# ADC_ADC_CFG_502C0000h register map
Vendor: Texas Instruments
Registers are 16-bit, read-write, reset values left out (the file's numbers can be read two ways) unless marked. A register's access mark holds for its fields unless they carry their own. Offsets are as the file gives them; [hi:lo] are bit positions; {n}, {i} and the like mark numbered series.

## ADC_CFG (part 3 of 3)
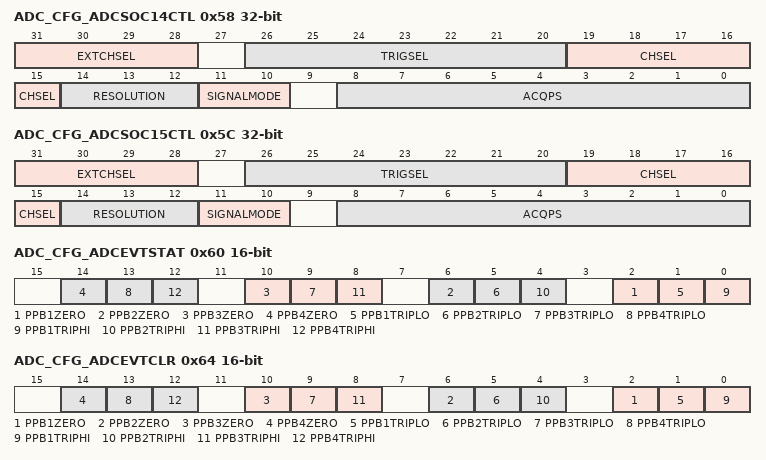
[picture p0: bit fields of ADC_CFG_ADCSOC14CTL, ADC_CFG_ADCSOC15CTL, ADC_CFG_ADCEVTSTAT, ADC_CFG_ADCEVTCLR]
0x58 ADC_CFG_ADCSOC14CTL 32-bit access per field — ADC SOC14 Control Register.
  [31:28] EXTCHSEL rw — SOC14 External Channel Mux Select. Selects the external mux combination to output when SOC14 is received by the ADC. Some or all of the ADCEXTMUX lines can be enabled via the device GPIO mux to control an external analog mux.
  [26:20] TRIGSEL rw — SOC14 Trigger Source Select. Along with the SOC14 field in the ADCINTSOCSEL1 register, this bit field configures which trigger will set the SOC14 flag in the ADCSOCFLG1 register to initiate a conversion to start once priority is given to it. Note: SOCFRC1 register can always be used to software trigger SOCs in addition to any hardware trigger configuration. 00h ADCTRIG0 - Software only 01h ADCTRIG1 - RTI0 Timer 02h ADCTRIG2 - RTI1 Timer 03h ADCTRIG3 - RTI2 Timer 04h ADCTRIG4 - RTI3 Timer 05h ADCTRIG5 - InputXBAR.Out[5] 06h ADCTRIG6 - spare 07h ADCTRIG7 - spare 08h ADCTRIG8 - EPWM0, ADCSOCA 09h ADCTRIG9 - EPWM0, ADCSOCB 0Ah ADCTRIG10 - EPWM1, ADCSOCA 0Bh ADCTRIG11 - EPWM1, ADCSOCB 0Ch ADCTRIG12 - EPWM2, ADCSOCA 0Dh ADCTRIG13 - EPWM2, ADCSOCB 0Eh ADCTRIG14 - EPWM3, ADCSOCA 0Fh ADCTRIG15 - EPWM3, ADCSOCB .... EPWM4 to EPWM27 40h ADCTRIG64 - EPWM28, ADCSOCA 41h ADCTRIG65 - EPWM28, ADCSOCB 42h ADCTRIG66 - EPWM29, ADCSOCA 43h ADCTRIG67 - EPWM29, ADCSOCB 44h ADCTRIG68 - EPWM30, ADCSOCA 45h ADCTRIG69 - EPWM30, ADCSOCB 46h ADCTRIG70 - EPWM31, ADCSOCA 47h ADCTRIG71 - EPWM31, ADCSOCB 48h ADCTRIG72 - ECAP0, TRIGOUT .... ECAP1 to ECAP8 51h ADCTRIG81 - ECAP9, TRIGOUT 52h ADCTRIG82 - ECAP10, TRIGOUT .... 57h ADCTRIG87 - ECAP15, TRIGOUT 58h ADCTRIG88 - RTI4 Timer 59h ADCTRIG89 - RTI5 Timer 5Ah ADCTRIG90 - RTI6 Timer 5Bh ADCTRIG91 - RTI7 Timer .... 7Fh ADCTRIG127 - REP2TRIG - these are not external trigger signals on the ADC IP port. We need to configure them for internal selection of repeater triggers.
  [19:15] CHSEL rw — SOC14 Channel Select. Selects the channel to be converted when SOC14 is received by the ADC. Single-ended Signaling Mode [SIGNALMODE = 0]: 00h ADCIN0 01h ADCIN1 02h ADCIN2 03h ADCIN3 ... 1Dh ADCIN29 1Eh ADCIN30 1Fh ADCIN31 Differential Signaling Mode [SIGNALMODE = 1]: 00h ADCIN0 [non-inverting] and ADCIN1 [inverting] 01h ADCIN0 [non-inverting] and ADCIN1 [inverting] 02h ADCIN2 [non-inverting] and ADCIN3 [inverting] 03h ADCIN2 [non-inverting] and ADCIN3 [inverting] 04h ADCIN4 [non-inverting] and ADCIN5 [inverting] 05h ADCIN4 [non-inverting] and ADCIN5 [inverting] ... 0Eh ADCIN26 [non-inverting] and ADCIN27 [inverting] 0Fh ADCIN26 [non-inverting] and ADCIN27 [inverting] 10h ADCIN28 [non-inverting] and ADCIN29 [inverting] 11h ADCIN28 [non-inverting] and ADCIN29 [inverting] 1Eh ADCIN30 [non-inverting] and ADCIN31 [inverting] 1Fh ADCIN30 [non-inverting] and ADCIN31 [inverting]
  [14:12] RESOLUTION ro — Placeholder for per-SOC resolution
  [11:10] SIGNALMODE ro — Placeholder for per-SOC signal mode
  [8:0] ACQPS rw — SOC14 Acquisition Prescale. Controls the sample and hold window for this SOC. 000h Reserved 001h Reserved 002h Sample window is 3 system clock cycles wide 003h Sample window is 4 system clock cycles wide ... 1FFh Sample window is 512 system clock cycles wide The configured acquisition time must be at least as long as one ADCCLK cycle for correct ADC operation. The configured acquisition time must also be at least 3 SYSCLK cycles long. The device datasheet will also specify a minimum sample and hold window duration.
0x5C ADC_CFG_ADCSOC15CTL 32-bit access per field — ADC SOC15 Control Register.
  [31:28] EXTCHSEL rw — SOC15 External Channel Mux Select. Selects the external mux combination to output when SOC15 is received by the ADC. Some or all of the ADCEXTMUX lines can be enabled via the device GPIO mux to control an external analog mux.
  [26:20] TRIGSEL rw — SOC15 Trigger Source Select. Along with the SOC15 field in the ADCINTSOCSEL1 register, this bit field configures which trigger will set the SOC15 flag in the ADCSOCFLG1 register to initiate a conversion to start once priority is given to it. Note: SOCFRC1 register can always be used to software trigger SOCs in addition to any hardware trigger configuration. 00h ADCTRIG0 - Software only 01h ADCTRIG1 - RTI0 Timer 02h ADCTRIG2 - RTI1 Timer 03h ADCTRIG3 - RTI2 Timer 04h ADCTRIG4 - RTI3 Timer 05h ADCTRIG5 - InputXBAR.Out[5] 06h ADCTRIG6 - spare 07h ADCTRIG7 - spare 08h ADCTRIG8 - EPWM0, ADCSOCA 09h ADCTRIG9 - EPWM0, ADCSOCB 0Ah ADCTRIG10 - EPWM1, ADCSOCA 0Bh ADCTRIG11 - EPWM1, ADCSOCB 0Ch ADCTRIG12 - EPWM2, ADCSOCA 0Dh ADCTRIG13 - EPWM2, ADCSOCB 0Eh ADCTRIG14 - EPWM3, ADCSOCA 0Fh ADCTRIG15 - EPWM3, ADCSOCB .... EPWM4 to EPWM27 40h ADCTRIG64 - EPWM28, ADCSOCA 41h ADCTRIG65 - EPWM28, ADCSOCB 42h ADCTRIG66 - EPWM29, ADCSOCA 43h ADCTRIG67 - EPWM29, ADCSOCB 44h ADCTRIG68 - EPWM30, ADCSOCA 45h ADCTRIG69 - EPWM30, ADCSOCB 46h ADCTRIG70 - EPWM31, ADCSOCA 47h ADCTRIG71 - EPWM31, ADCSOCB 48h ADCTRIG72 - ECAP0, TRIGOUT .... ECAP1 to ECAP8 51h ADCTRIG81 - ECAP9, TRIGOUT 52h ADCTRIG82 - ECAP10, TRIGOUT .... 57h ADCTRIG87 - ECAP15, TRIGOUT 58h ADCTRIG88 - RTI4 Timer 59h ADCTRIG89 - RTI5 Timer 5Ah ADCTRIG90 - RTI6 Timer 5Bh ADCTRIG91 - RTI7 Timer .... 7Fh ADCTRIG127 - REP2TRIG - these are not external trigger signals on the ADC IP port. We need to configure them for internal selection of repeater triggers.
  [19:15] CHSEL rw — SOC15 Channel Select. Selects the channel to be converted when SOC15 is received by the ADC. Single-ended Signaling Mode [SIGNALMODE = 0]: 00h ADCIN0 01h ADCIN1 02h ADCIN2 03h ADCIN3 ... 1Dh ADCIN29 1Eh ADCIN30 1Fh ADCIN31 Differential Signaling Mode [SIGNALMODE = 1]: 00h ADCIN0 [non-inverting] and ADCIN1 [inverting] 01h ADCIN0 [non-inverting] and ADCIN1 [inverting] 02h ADCIN2 [non-inverting] and ADCIN3 [inverting] 03h ADCIN2 [non-inverting] and ADCIN3 [inverting] 04h ADCIN4 [non-inverting] and ADCIN5 [inverting] 05h ADCIN4 [non-inverting] and ADCIN5 [inverting] ... 0Eh ADCIN26 [non-inverting] and ADCIN27 [inverting] 0Fh ADCIN26 [non-inverting] and ADCIN27 [inverting] 10h ADCIN28 [non-inverting] and ADCIN29 [inverting] 11h ADCIN28 [non-inverting] and ADCIN29 [inverting] 1Eh ADCIN30 [non-inverting] and ADCIN31 [inverting] 1Fh ADCIN30 [non-inverting] and ADCIN31 [inverting]
  [14:12] RESOLUTION ro — Placeholder for per-SOC resolution
  [11:10] SIGNALMODE ro — Placeholder for per-SOC signal mode
  [8:0] ACQPS rw — SOC15 Acquisition Prescale. Controls the sample and hold window for this SOC. 000h Reserved 001h Reserved 002h Sample window is 3 system clock cycles wide 003h Sample window is 4 system clock cycles wide ... 1FFh Sample window is 512 system clock cycles wide The configured acquisition time must be at least as long as one ADCCLK cycle for correct ADC operation. The configured acquisition time must also be at least 3 SYSCLK cycles long. The device datasheet will also specify a minimum sample and hold window duration.
0x60 ADC_CFG_ADCEVTSTAT ro — ADC Event Status Register.
  [4n-2] PPB{n}ZERO (n=1..4) — Post Processing Block {n} Zero Crossing Flag. When set indicates the ADCPPB{n}RESULT register has changed sign. This bit is gated by EOC signal. Note: these bits are set even when the corresponding enable in ADCEVTINTSEL is not set. Because of this, an ISR may need to examine both the ADCEVTSTAT and ADCEVTINTSEL registers to determine the source of the interrupt. Note: If software sets the clear bit on the same cycle that hardware is trying to set the flag bit, then hardware has priority
  [4n-3] PPB{n}TRIPLO (n=1..4) — Post Processing Block {n} Trip Low Flag. When set indicates a digital compare trip low event has occurred. Note: these bits are set even when the corresponding enable in ADCEVTINTSEL is not set. Because of this, an ISR may need to examine both the ADCEVTSTAT and ADCEVTINTSEL registers to determine the source of the interrupt. Note: If software sets the clear bit on the same cycle that hardware is trying to set the flag bit, then hardware has priority
  [4n-4] PPB{n}TRIPHI (n=1..4) — Post Processing Block {n} Trip High Flag. When set indicates a digital compare trip high event has occurred. Note: these bits are set even when the corresponding enable in ADCEVTINTSEL is not set. Because of this, an ISR may need to examine both the ADCEVTSTAT and ADCEVTINTSEL registers to determine the source of the interrupt. Note: If software sets the clear bit on the same cycle that hardware is trying to set the flag bit, then hardware has priority
0x64 ADC_CFG_ADCEVTCLR access not given — ADC Event Clear Register.
  [4n-2] PPB{n}ZERO (n=1..4) — Post Processing Block {n} Zero Crossing Clear. Clears the corresponding zero crossing flag in the ADCEVTSTAT register. Note: If software sets the clear bit on the same cycle that hardware is trying to set the flag bit, then hardware has priority (access R/W1TS)
  [4n-3] PPB{n}TRIPLO (n=1..4) — Post Processing Block {n} Trip Low Clear. Clears the corresponding trip low flag in the ADCEVTSTAT register. Note: If software sets the clear bit on the same cycle that hardware is trying to set the flag bit, then hardware has priority (access R/W1TS)
  [4n-4] PPB{n}TRIPHI (n=1..4) — Post Processing Block {n} Trip High Clear. Clears the corresponding trip high flag in the ADCEVTSTAT register. Note: If software sets the clear bit on the same cycle that hardware is trying to set the flag bit, then hardware has priority (access R/W1TS)
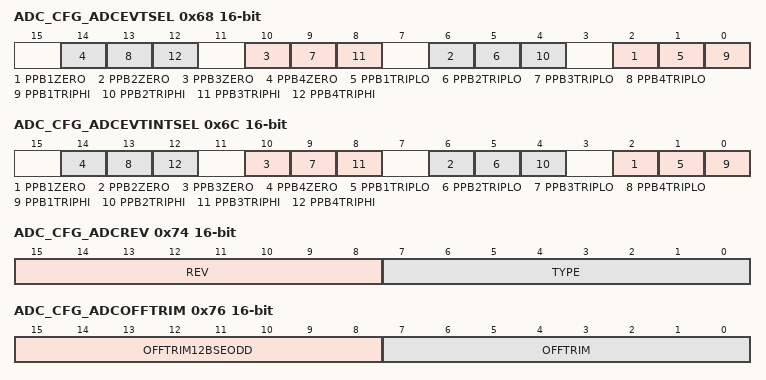
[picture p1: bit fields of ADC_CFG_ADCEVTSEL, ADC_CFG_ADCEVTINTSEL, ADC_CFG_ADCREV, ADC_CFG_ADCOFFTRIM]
0x68 ADC_CFG_ADCEVTSEL — ADC Event Selection Register.
  [4n-2] PPB{n}ZERO (n=1..4) — Post Processing Block {n} Zero Crossing Event Enable. Setting this bit allows the corresponding rising zero crossing flag to activate the event signal to the PWM blocks. The flag must be cleared before it can produce additional events to the PWM blocks.
  [4n-3] PPB{n}TRIPLO (n=1..4) — Post Processing Block {n} Trip Low Event Enable. Setting this bit allows the corresponding rising trip low flag to activate the event signal to the PWM blocks. The flag must be cleared before it can produce additional events to the PWM blocks.
  [4n-4] PPB{n}TRIPHI (n=1..4) — Post Processing Block {n} Trip High Event Enable. Setting this bit allows the corresponding rising trip high flag to activate the event signal to the PWM blocks. The flag must be cleared before it can produce additional events to the PWM blocks.
0x6C ADC_CFG_ADCEVTINTSEL — ADC Event Interrupt Selection Register.
  [4n-2] PPB{n}ZERO (n=1..4) — Post Processing Block {n} Zero Crossing Interrupt Enable. Setting this bit allows the corresponding rising zero crossing flag to activate the event interrupt signal to the PIE. The flag must be cleared before it can produce additional interrupts to the PIE.
  [4n-3] PPB{n}TRIPLO (n=1..4) — Post Processing Block {n} Trip Low Interrupt Enable. Setting this bit allows the corresponding rising trip low flag to activate the event interrupt signal to the PIE. The flag must be cleared before it can produce additional interrupts to the PIE.
  [4n-4] PPB{n}TRIPHI (n=1..4) — Post Processing Block {n} Trip High Interrupt Enable. Setting this bit allows the corresponding rising trip high flag to activate the event interrupt signal to the PIE. The flag must be cleared before it can produce additional interrupts to the PIE.
0x70 ADC_CFG_ADCOSDETECT — ADC Open and Shorts Detect Register.
  [2:0] DETECTCFG — ADC Opens and Shorts Detect Configuration. This bit field defines the open/shorts detection circuit state. 0h Open/Shorts detection circuit is disabled. 1h Open/Shorts detection circuit is enabled at zero scale. 2h Open/Shorts detection circuit is enabled at full scale. 3h Open/Shorts detection circuit is enabled at [nominal] 5/12 scale. 4h Open/Shorts detection circuit is enabled at [nominal] 7/12 scale. 5h Open/Shorts detection circuit is enabled with a [nominal] 5K pulldown to VSSA. 6h Open/Shorts detection circuit is enabled with a [nominal] 5K pullup to VDDA. 7h Open/Shorts detection circuit is enabled with a [nominal] 7K pulldown to VSSA.
0x72 ADC_CFG_ADCCOUNTER ro — ADC Counter Register.
  [11:0] FREECOUNT — ADC Free Running Counter Value. This bit field reflects the status of the free running ADC counter.
0x74 ADC_CFG_ADCREV ro — ADC Revision Register.
  [15:8] REV — ADC Revision. To allow documentation of differences between revisions. First version is labeled as00h
  [7:0] TYPE — ADC Type. Always set to 5 for this ADC.
0x76 ADC_CFG_ADCOFFTRIM — ADC Offset Trim Register.
  [15:8] OFFTRIM12BSEODD — If ADCCLT2.OFFTRIMMODE = 1, then this register will supply offset trim when the ADC is in 12-bit single-ended mode for odd channels. Range is +127 steps to -128 steps [2's compliment format]. Regardless of the converter resolution, the size of each trim step is [VREFHI-VREFLO]/65536.
  [7:0] OFFTRIM — ADC Offset Trim. Adjusts the conversion results of the converter up or down to account for offset error in the ADC. A different offset trim is required for each combination of resolution and signal mode. If ADCCTL2.OFFTRIMMODE = 0, then using the AdcSetMode function to set the resolution and signal mode will ensure that the correct offset trim is loaded into this register. If ADCCLT2.OFFTRIMMODE = 1, then this register will supply offset trim only when the ADC is in 12-bit single-ended mode and only for even channels. Range is +127 steps to -128 steps [2's compliment format]. Regardless of the converter resolution, the size of each trim step is [VREFHI-VREFLO]/65536.
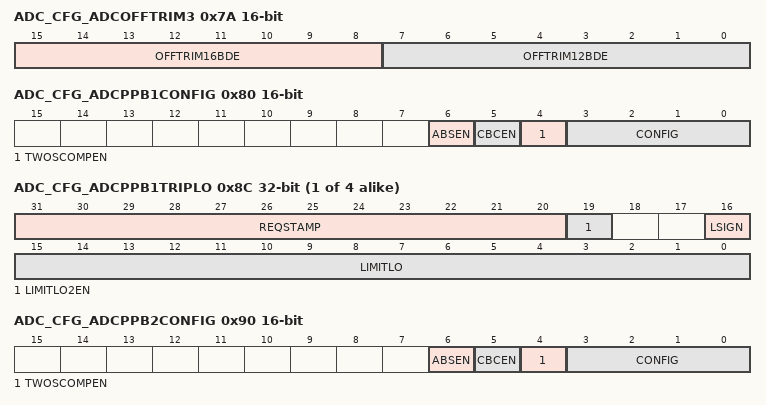
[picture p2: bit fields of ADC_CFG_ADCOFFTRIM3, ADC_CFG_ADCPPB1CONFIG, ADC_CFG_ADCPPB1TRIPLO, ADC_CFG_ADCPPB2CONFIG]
0x7A ADC_CFG_ADCOFFTRIM3 — ADC Offset Trim Register.
  [15:8] OFFTRIM16BDE — If ADCCLT2.OFFTRIMMODE = 1, then this register will supply offset trim when the ADC is in 16-bit differential mode. Range is +127 steps to -128 steps [2's compliment format]. Regardless of the converter resolution, the size of each trim step is [VREFHI-VREFLO]/65536.
  [7:0] OFFTRIM12BDE — If ADCCLT2.OFFTRIMMODE = 1, then this register will supply offset trim when the ADC is in 12-bit differential mode. Range is +127 steps to -128 steps [2's compliment format]. Regardless of the converter resolution, the size of each trim step is [VREFHI-VREFLO]/65536.
0x80 ADC_CFG_ADCPPB1CONFIG — ADC PPB1 Config Register.
  [6] ABSEN — ADC Post Processing Block 1 Absolute Value Enable. When set this bit enables absolute value calculation on the ADCRESULx associated with ADCPPB1. This occurs before the TWOSCOMPEN logic is evaluated [so enabling both TWOSCOMPEN and ABSEN will always result in a negative value stored in ADCPPBxRESULT] 0 ADCPPB1RESULT = ADCRESULTx - ADCPPB1OFFREF 1 ADCPPB1RESULT = abs[ADCRESULTx - ADCPPB1OFFREF]
  [5] CBCEN — ADC Post Processing Block Cycle By Cycle Enable. When set, this bit enables the post conversion hardware processing circuit to automatically clear the ADCEVTSTAT on a conversion if the event condition is no longer present.
  [4] TWOSCOMPEN — ADC Post Processing Block 1 Two's Complement Enable. When set this bit enables the post conversion hardware processing circuit that performs a two's complement on the output of the offset/reference subtraction unit before storing the result in the ADCPPB1RESULT register. 0 ADCPPB1RESULT = ADCRESULTx - ADCPPB1OFFREF 1 ADCPPB1RESULT = ADCPPB1OFFREF - ADCRESULTx
  [3:0] CONFIG — ADC Post Processing Block 1 Configuration. This bit field defines which SOC/EOC/RESULT is associated with this post processing block. 0000 SOC0/EOC0/RESULT0 is associated with post processing block 1 0001 SOC1/EOC1/RESULT1 is associated with post processing block 1 0010 SOC2/EOC2/RESULT2 is associated with post processing block 1 0011 SOC3/EOC3/RESULT3 is associated with post processing block 1 0100 SOC4/EOC4/RESULT4 is associated with post processing block 1 0101 SOC5/EOC5/RESULT5 is associated with post processing block 1 0110 SOC6/EOC6/RESULT6 is associated with post processing block 1 0111 SOC7/EOC7/RESULT7 is associated with post processing block 1 1000 SOC8/EOC8/RESULT8 is associated with post processing block 1 1001 SOC9/EOC9/RESULT9 is associated with post processing block 1 1010 SOC10/EOC10/RESULT10 is associated with post processing block 1 1011 SOC11/EOC11/RESULT11 is associated with post processing block 1 1100 SOC12/EOC12/RESULT12 is associated with post processing block 1 1101 SOC13/EOC13/RESULT13 is associated with post processing block 1 1110 SOC14/EOC14/RESULT14 is associated with post processing block 1 1111 SOC15/EOC15/RESULT15 is associated with post processing block 1
{0x72+0x10*i} ADC_CFG_ADCPPB{i}STAMP ro (i=1..4) — ADC PPB{i} Sample Delay Time Stamp Register.
  [11:0] DLYSTAMP — ADC Post Processing Block {i} Delay Time Stamp. When an SOC starts sampling the value contained in REQSTAMP is subtracted from the value in ADCCOUNTER.FREECOUNT and loaded into this bit field, thereby giving the number of system clock cycles delay between the SOC trigger and the actual start of the sample.
{0x74+0x10*i} ADC_CFG_ADCPPB{i}OFFCAL (i=1..4) — ADC PPB{i} Offset Calibration Register.
  [9:0] OFFCAL — ADC Post Processing Block {i} Offset Correction. This bit field can be used to digitally remove any system level offset inherent in the ADCIN circuit. This 10-bit signed value is subtracted from the ADC output before being stored in the ADCRESULT register. 000h No change. The ADC output is stored directly into ADCRESULT. 001h ADC output - 1 is stored into ADCRESULT. 002h ADC output - 2 is stored into ADCRESULT. ... 200h ADC output + 512 is stored into ADCRESULT. ... 3FFh ADC output + 1 is stored into ADCRESULT. NOTE: In 16-bit mode, the subtraction will saturate at0000hand FFFFh before being stored into the ADCRESULT register. In 12-bit mode, the subtraction will saturate at0000hand 0FFFh before being stored into the ADCRESULT register. Note: in the case that multiple PPBs point to the same SOC, only the OFFCAL of the lowest numbered PPB will be applied.
{0x76+0x10*i} ADC_CFG_ADCPPB{i}OFFREF (i=1..4) — ADC PPB{i} Offset Reference Register.
  [15:0] OFFREF — ADC Post Processing Block {i} Offset Correction. This bit field can be used to either calculate the feedback error or convert a unipolar signal to bipolar by subtracting a reference value. This 16-bit unsigned value is subtracted from the ADCRESULT register before being passed through an optional two's complement function and stored in the ADCPPB{i}RESULT register. This subtraction is not saturated. 0000h No change. The ADCRESULT value is passed on. 0001h ADCRESULT - 1 is passed on. 0002h ADCRESULT - 2 is passed on. ... 8000h ADCRESULT - 32,768 is passed on. ... FFFFh ADCRESULT - 65,535 is passed on. NOTE: In 12-bit mode the size of this register does not change from 16-bits. It is the user's responsibility to ensure that only a 12-bit value is written to this register when in 12-bit mode.
{0x78+0x10*i} ADC_CFG_ADCPPB{i}TRIPHI 32-bit (i=1..4) — ADC PPB{i} Trip High Register.
  [23:0] LIMITHI — ADC Post Processing Block {i} Trip High Limit. This value sets the digital comparator trip high limit. When comparing to an ADCPPBxRESULT register, the upper bits will be ignored: - TRIPHI[23:17] will be ignored in 16 bit mode - TRIPHI[23:13] will be ignored in 12 bit mode
{0x7C+0x10*i} ADC_CFG_ADCPPB{i}TRIPLO 32-bit access per field (i=1..4) — ADC PPB{i} Trip Low/Trigger Time Stamp Register.
  [31:20] REQSTAMP ro — ADC Post Processing Block {i} Request Time Stamp. When a trigger sets the associated SOC flag in the ADCSOCFLG1 register the value of ADCCOUNTER.FREECOUNT is loaded into this bit field.
  [19] LIMITLO2EN rw — Extended Low Limit 2 Enable. 0 = Low limit set by ADCPPB{i}TRIPLO register. Not compatible with comparison with ADCPPB{i}PSUM or ADCPPB{i}SUM 1 = Low limit set by ADCPPB{i}TRIPLO2 register
  [16] LSIGN rw — Low Limit Sign Bit. This is the sign bit [17th bit] to the LIMITLO bit field when in 16-bit ADC mode.
  [15:0] LIMITLO rw — ADC Post Processing Block {i} Trip Low Limit. This value sets the digital comparator trip low limit. In 16-bit mode all 17 bits will be compared against the 17 bits of the PPBRESULT bit field of the ADCPPB{i}RESULT register. In 12-bit mode bits 12:0 will be compared against bits 12:0 of the PPBRSULT bit field of the ADCPPB{i}RESULT register.
0x90 ADC_CFG_ADCPPB2CONFIG — ADC PPB2 Config Register.
  [6] ABSEN — ADC Post Processing Block 2 Absolute Value Enable. When set this bit enables absolute value calculation on the ADCRESULx associated with ADCPPB2. This occurs before the TWOSCOMPEN logic is evaluated [so enabling both TWOSCOMPEN and ABSEN will always result in a negative value stored in ADCPPBxRESULT] 0 ADCPPB2RESULT = ADCRESULTx - ADCPPB2OFFREF 1 ADCPPB2RESULT = abs[ADCRESULTx - ADCPPB2OFFREF]
  [5] CBCEN — ADC Post Processing Block Cycle By Cycle Enable. When set, this bit enables the post conversion hardware processing circuit to automatically clear the ADCEVTSTAT on a conversion if the event condition is no longer present.
  [4] TWOSCOMPEN — ADC Post Processing Block 2 Two's Complement Enable. When set this bit enables the post conversion hardware processing circuit that performs a two's complement on the output of the offset/reference subtraction unit before storing the result in the ADCPPB2RESULT register. 0 ADCPPB2RESULT = ADCRESULTx - ADCPPB2OFFREF 1 ADCPPB2RESULT = ADCPPB2OFFREF - ADCRESULTx
  [3:0] CONFIG — ADC Post Processing Block 2 Configuration. This bit field defines which SOC/EOC/RESULT is associated with this post processing block. 0000 SOC0/EOC0/RESULT0 is associated with post processing block 2 0001 SOC1/EOC1/RESULT1 is associated with post processing block 2 0010 SOC2/EOC2/RESULT2 is associated with post processing block 2 0011 SOC3/EOC3/RESULT3 is associated with post processing block 2 0100 SOC4/EOC4/RESULT4 is associated with post processing block 2 0101 SOC5/EOC5/RESULT5 is associated with post processing block 2 0110 SOC6/EOC6/RESULT6 is associated with post processing block 2 0111 SOC7/EOC7/RESULT7 is associated with post processing block 2 1000 SOC8/EOC8/RESULT8 is associated with post processing block 2 1001 SOC9/EOC9/RESULT9 is associated with post processing block 2 1010 SOC10/EOC10/RESULT10 is associated with post processing block 2 1011 SOC11/EOC11/RESULT11 is associated with post processing block 2 1100 SOC12/EOC12/RESULT12 is associated with post processing block 2 1101 SOC13/EOC13/RESULT13 is associated with post processing block 2 1110 SOC14/EOC14/RESULT14 is associated with post processing block 2 1111 SOC15/EOC15/RESULT15 is associated with post processing block 2
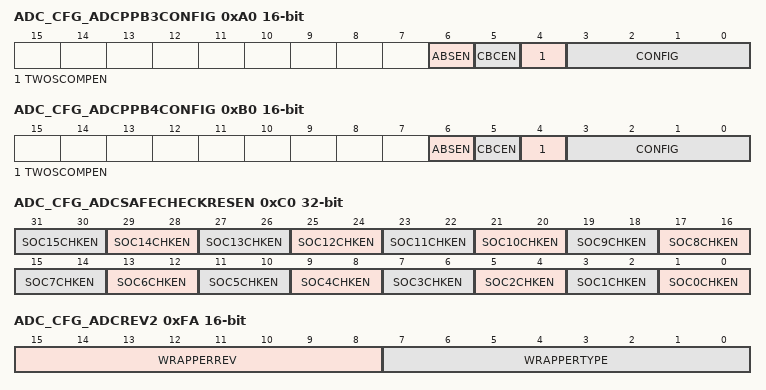
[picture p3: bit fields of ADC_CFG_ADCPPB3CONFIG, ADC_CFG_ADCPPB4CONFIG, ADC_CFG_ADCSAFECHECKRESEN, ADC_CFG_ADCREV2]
0xA0 ADC_CFG_ADCPPB3CONFIG — ADC PPB3 Config Register.
  [6] ABSEN — ADC Post Processing Block 3 Absolute Value Enable. When set this bit enables absolute value calculation on the ADCRESULx associated with ADCPPB3. This occurs before the TWOSCOMPEN logic is evaluated [so enabling both TWOSCOMPEN and ABSEN will always result in a negative value stored in ADCPPBxRESULT] 0 ADCPPB3RESULT = ADCRESULTx - ADCPPB3OFFREF 1 ADCPPB3RESULT = abs[ADCRESULTx - ADCPPB3OFFREF]
  [5] CBCEN — ADC Post Processing Block Cycle By Cycle Enable. When set, this bit enables the post conversion hardware processing circuit to automatically clear the ADCEVTSTAT on a conversion if the event condition is no longer present.
  [4] TWOSCOMPEN — ADC Post Processing Block 3 Two's Complement Enable. When set this bit enables the post conversion hardware processing circuit that performs a two's complement on the output of the offset/reference subtraction unit before storing the result in the ADCPPB3RESULT register. 0 ADCPPB3RESULT = ADCRESULTx - ADCPPB3OFFREF 1 ADCPPB3RESULT = ADCPPB3OFFREF - ADCRESULTx
  [3:0] CONFIG — ADC Post Processing Block 3 Configuration. This bit field defines which SOC/EOC/RESULT is associated with this post processing block. 0000 SOC0/EOC0/RESULT0 is associated with post processing block 3 0001 SOC1/EOC1/RESULT1 is associated with post processing block 3 0010 SOC2/EOC2/RESULT2 is associated with post processing block 3 0011 SOC3/EOC3/RESULT3 is associated with post processing block 3 0100 SOC4/EOC4/RESULT4 is associated with post processing block 3 0101 SOC5/EOC5/RESULT5 is associated with post processing block 3 0110 SOC6/EOC6/RESULT6 is associated with post processing block 3 0111 SOC7/EOC7/RESULT7 is associated with post processing block 3 1000 SOC8/EOC8/RESULT8 is associated with post processing block 3 1001 SOC9/EOC9/RESULT9 is associated with post processing block 3 1010 SOC10/EOC10/RESULT10 is associated with post processing block 3 1011 SOC11/EOC11/RESULT11 is associated with post processing block 3 1100 SOC12/EOC12/RESULT12 is associated with post processing block 3 1101 SOC13/EOC13/RESULT13 is associated with post processing block 3 1110 SOC14/EOC14/RESULT14 is associated with post processing block 3 1111 SOC15/EOC15/RESULT15 is associated with post processing block 3
0xB0 ADC_CFG_ADCPPB4CONFIG — ADC PPB4 Config Register.
  [6] ABSEN — ADC Post Processing Block 4 Absolute Value Enable. When set this bit enables absolute value calculation on the ADCRESULx associated with ADCPPB4. This occurs before the TWOSCOMPEN logic is evaluated [so enabling both TWOSCOMPEN and ABSEN will always result in a negative value stored in ADCPPBxRESULT] 0 ADCPPB4RESULT = ADCRESULTx - ADCPPB4OFFREF 1 ADCPPB4RESULT = abs[ADCRESULTx - ADCPPB4OFFREF]
  [5] CBCEN — ADC Post Processing Block Cycle By Cycle Enable. When set, this bit enables the post conversion hardware processing circuit to automatically clear the ADCEVTSTAT on a conversion if the event condition is no longer present.
  [4] TWOSCOMPEN — ADC Post Processing Block 4 Two's Complement Enable. When set this bit enables the post conversion hardware processing circuit that performs a two's complement on the output of the offset/reference subtraction unit before storing the result in the ADCPPB4RESULT register. 0 ADCPPB4RESULT = ADCRESULTx - ADCPPB4OFFREF 1 ADCPPB4RESULT = ADCPPB4OFFREF - ADCRESULTx
  [3:0] CONFIG — ADC Post Processing Block 4 Configuration. This bit field defines which SOC/EOC/RESULT is associated with this post processing block. 0000 SOC0/EOC0/RESULT0 is associated with post processing block 4 0001 SOC1/EOC1/RESULT1 is associated with post processing block 4 0010 SOC2/EOC2/RESULT2 is associated with post processing block 4 0011 SOC3/EOC3/RESULT3 is associated with post processing block 4 0100 SOC4/EOC4/RESULT4 is associated with post processing block 4 0101 SOC5/EOC5/RESULT5 is associated with post processing block 4 0110 SOC6/EOC6/RESULT6 is associated with post processing block 4 0111 SOC7/EOC7/RESULT7 is associated with post processing block 4 1000 SOC8/EOC8/RESULT8 is associated with post processing block 4 1001 SOC9/EOC9/RESULT9 is associated with post processing block 4 1010 SOC10/EOC10/RESULT10 is associated with post processing block 4 1011 SOC11/EOC11/RESULT11 is associated with post processing block 4 1100 SOC12/EOC12/RESULT12 is associated with post processing block 4 1101 SOC13/EOC13/RESULT13 is associated with post processing block 4 1110 SOC14/EOC14/RESULT14 is associated with post processing block 4 1111 SOC15/EOC15/RESULT15 is associated with post processing block 4
0xC0 ADC_CFG_ADCSAFECHECKRESEN 32-bit — ADC Safe Check Result Enable Register.
  [2n+1:2n] SOC{n}CHKEN (n=0..15) — Determine which result will be passed to the safety result checker. Only one of the raw ADC result, the PPB result, or the final PPB accumulated SUM can be passed on to the checker for each conversion. 00 No result passed to safety checker 01 ADCRESULT{n} passed to safety checker 10 PPB Result associated with SOC{n} passed to safety checker 11 PPB Sum associated with SOC{n} passed to safety chekcer Note: if multiple PPBs point to the same SOC, the highest numbered PPB will have priority to pass its result to the safety checker
0xDE ADC_CFG_ADCINTCYCLE — ADC Early Interrupt Generation Cycle.
  [15:0] DELAY — ADC Early Interrupt Generation Cycle Delay: Defines the delay from the fall edge of ADCSOC in terms of system clock cycles, for the interrupt to be generated.
{0xDC+4i} ADC_CFG_ADCINLTRIM{i} 32-bit (i=1..6) — ADC Linearity Trim {i} Register.
  [31:0] INLTRIM{32i-1}TO{32i-32} — ADC Linearity Trim Bits {32i-1}-{32i-32}. This register should not be modified unless specifically indicated by TI Errata or other documentation. Modifying the contents of this register could cause this module to operate outside of datasheet specifications.
0xFA ADC_CFG_ADCREV2 ro — ADC Wrapper Revision Register.
  [15:8] WRAPPERREV — ADC Revision. To allow documentation of differences between revisions. First version is labeled as00h
  [7:0] WRAPPERTYPE — ADC Wrapper Type. Always set to 4 for this ADC.
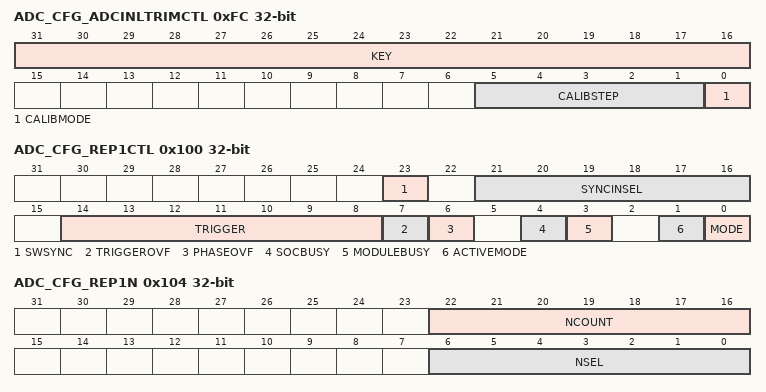
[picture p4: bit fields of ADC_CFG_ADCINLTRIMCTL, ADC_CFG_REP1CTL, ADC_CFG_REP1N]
0xFC ADC_CFG_ADCINLTRIMCTL 32-bit — ADC Linearity Trim Control Register.
  [31:16] KEY — ADC Linearity Trim Control Write Key. Any write to this register must contain the value 0xA5A5 in these bit locations. If a write request attempts to load any other value into these bits, the write for the entire register is ignored. These bits always read back a zero.
  [5:1] CALIBSTEP — ADC Linearity Calibration Step. Defines which of the 24 steps of calibration is to be executed. Never set this bit field while the ADC SELFTRIM is in progress. The R-M-W operation could unintentionally set the CALIBMODE bit again.
  [0] CALIBMODE — ADC Linearity Calibration Mode.
0x100 ADC_CFG_REP1CTL 32-bit access not given — ADC Trigger Repeater 1 Control Register.
  [23] SWSYNC — Trigger repeater 1 software force sync. On a sync. event, all registers in repeater 1 are reset to a ready and waiting state. Values of NSEL, PHASE, and MODE are preserved. Note: SOCs associated with repeater 1 are not cleared. (access R/W1TS)
  [21:16] SYNCINSEL rw — Trigger repeater 1 sync. input select. On a sync. event, all registers in repeater 1 are reset to a ready and waiting state. Values of NSEL, PHASE, and MODE are preserved. Note: SOCs associated with repeater 1 are not cleared.
  [14:8] TRIGGER rw — ADC Trigger Repeater 1 Trigger Select. Selects the trigger to modify via oversampling or undersampling. 00h REPTRIG0 - Software only 01h REPTRIG1 - RTI0 Timer 02h REPTRIG2 - RTI1 Timer 03h REPTRIG3 - RTI2 Timer 04h REPTRIG4 - RTI3 Timer 05h REPTRIG5 - InputXBAR.Out[5] 06h REPTRIG6 - spare 07h REPTRIG7 - spare 08h REPTRIG8 - EPWM0, ADCSOCA 09h REPTRIG9 - EPWM0, ADCSOCB 0Ah REPTRIG10 - EPWM1, ADCSOCA 0Bh REPTRIG11 - EPWM1, ADCSOCB 0Ch REPTRIG12 - EPWM2, ADCSOCA 0Dh REPTRIG13 - EPWM2, ADCSOCB 0Eh REPTRIG14 - EPWM3, ADCSOCA 0Fh REPTRIG15 - EPWM3, ADCSOCB .... EPWM4 to EPWM27 40h REPTRIG64 - EPWM28, ADCSOCA 41h REPTRIG65 - EPWM28, ADCSOCB 42h REPTRIG66 - EPWM29, ADCSOCA 43h REPTRIG67 - EPWM29, ADCSOCB 44h REPTRIG68 - EPWM30, ADCSOCA 45h REPTRIG69 - EPWM30, ADCSOCB 46h REPTRIG70 - EPWM31, ADCSOCA 47h REPTRIG71 - EPWM31, ADCSOCB 48h REPTRIG72 - ECAP0, TRIGOUT .... ECAP1 to ECAP8 51h REPTRIG81 - ECAP9, TRIGOUT 52h REPTRIG82 - ECAP10, TRIGOUT .... 57h REPTRIG73 - ECAP15, TRIGOUT 58h REPTRIG1 - RTI4 Timer 59h REPTRIG1 - RTI5 Timer 5Ah REPTRIG1 - RTI6 Timer 5Bh REPTRIG1 - RTI7 Timer .... 7Fh - Reserved
  [7] TRIGGEROVF — ADC Trigger Repeater 1 Oversampled Trigger Overflow. Indicates that a trigger was dropped because a trigger arrived while the repeater was still generating repeated oversampled triggers [NCOUNT was not 0 or SOCs associated with Repeater 1 were still pending]. Writing a 1 will clear this flag. Note: This flag won't be set in undersampling mode or when NSEL = 0; if a trigger arrives before the previous SOCs have completed, the trigger will be passed and the overflow flags of the SOCs that were still pending will be set. Note: If software sets the clear bit on the same cycle that hardware is trying to set the flag bit, then hardware has priority and the overflow bit will not be set (access R/W1TC)
  [6] PHASEOVF — ADC Trigger Repeater 1 Phase Delay Overflow. Indicates that a trigger was dropped because a trigger arrived when the phase delay logic was still waiting to send the delayed trigger [PHASECOUNT was not 0]. Writing a 1 will clear this flag. Note: If software sets the clear bit on the same cycle that hardware is trying to set the flag bit, then hardware has priority and the overflow bit will not be set (access R/W1TC)
  [4] SOCBUSY ro — ADC Trigger Repeater 1 Associated SOCs Busy indicator. In oversampling mode: 0 = no SOCs associated with this repeater are pending 1 = SOCs associated with this repeater are still pending The next repeated trigger to the ADC in oversampling mode will not occur until SPREADCOUNT is 0 [minimum time is complete] and REP1CTL.BUSY = 0 [SOCs associated with trigger repeater 1 are no longer pending]. Note: If the ADC is in burstmode and the BURSTTRIG is Repeater 1, then all round-robin SOCs are considered associated with this repeater and the repeater will not re-trigger until there are no pending round-robin SOCs [in addition to any associated pending high-priority SOCs].
  [3] MODULEBUSY ro — ADC Trigger Repeater 1 Module Busy indicator. In oversampling mode: 0 = Repeater 1 is idle and can accept a new repeated trigger in oversampling mode 1 = Repeater 1 still has repeated triggers remaining [NCOUNT ' 0] or associated SOCs are still pending [SOCBUSY is 1] If a new oversampled trigger is received while the module is still busy, the TRIGGEROVF bit will be set and the trigger will be ignored.
  [1] ACTIVEMODE ro — When a trigger is recived in oversampling or undersampling mode the value of MODE is copied to ACTIVEMODE. ACTIVEMODE determines if the repeater will repeat of filter triggers. Changes to MODE while the repeater is working therefore won't cause any changes in functionality until the module becomes idle and then a new trigger is received. 0 = module is oversampling 1 = module is undersampling
  [0] MODE rw — ADC trigger repeater 1 mode selection. Select either oversampling or undersampling mode. In oversampling mode, when the trigger selected by REP1CTL.TRIGSEL is received, the repeater will repeat the trigger REP1N.NSEL + 1 times. In undersampling mode, when the trigger selected by REP1CTL.TRIGSEL is received the first time, the repeater will pass the trigger through. The next REP1N.NSEL triggers will be ignored. 0 = oversampling 1 = undersampling
0x104 ADC_CFG_REP1N 32-bit access per field — ADC Trigger Repeater 1 N Select Register.
  [22:16] NCOUNT ro — ADC trigger repeater 1 trigger count. In oversampling mode, indicates the number of triggers remaining to be generated. If a trigger is received corresponding to REP1CTL.TRIGSEL while NCOUNT is not 0 [the repeater is still busy generating the repeated triggers] then the trigger will be ignored and REP1CTL.TRIGOVF will be set to 1. In undersampling mode, indicates the number of triggers remaining to be supressed.
  [6:0] NSEL rw — ADC Trigger Repeater 1 selection of number of triggers. In oversampling mode, selects the number of repeated triggers. For each trigger received corresponding to REP1CTL.TRIGSEL, NSEL + 1 triggers will be generated. 0 = 1 trigger is generated [pass-through] 1 = 2 triggers are generated 2 = 3 triggers are generated ... 127 = 128 triggers are generated In undersampling mode, selects the number triggers to be supressed. 1 out NSEL + 1 triggers received corresponding to REP1CTL.TRIGSEL will be passed through [the first trigger will be passed through and the subsequent NSEL triggers will be supressed]. 0 = all triggers are passed 1 = 1 out of 2 triggers are passed 2 = 1 out of 3 triggers are passed ... 127 = 1 out of 128 triggers are passed
